# J7AEP_GPU_BXS464_WRAP0_GPU_SS_0_CORE_MMRS register map
Vendor: Texas Instruments
Registers are 64-bit, access per field, reset 0x0 unless marked. A register's access mark holds for its fields unless they carry their own. Offsets are as the file gives them; [hi:lo] are bit positions; lines under a group give offsets from that group; {n}, {i} and the like mark numbered series; 'fields as' and 'values as' point back to an identical list; <NAME> marks a mode.

## J7AEP_GPU_BXS464_WRAP0_GPU_SS_0_CORE_MMRS (part 4 of 4)
0x3970 CORE_MMRS_RGX_CR_SLC_SIZE_IN_KB ro reset 0x100
  [15:0] SIZE — The configured SLC SIZE in KBytes ie 0x0100 = 256 KB.
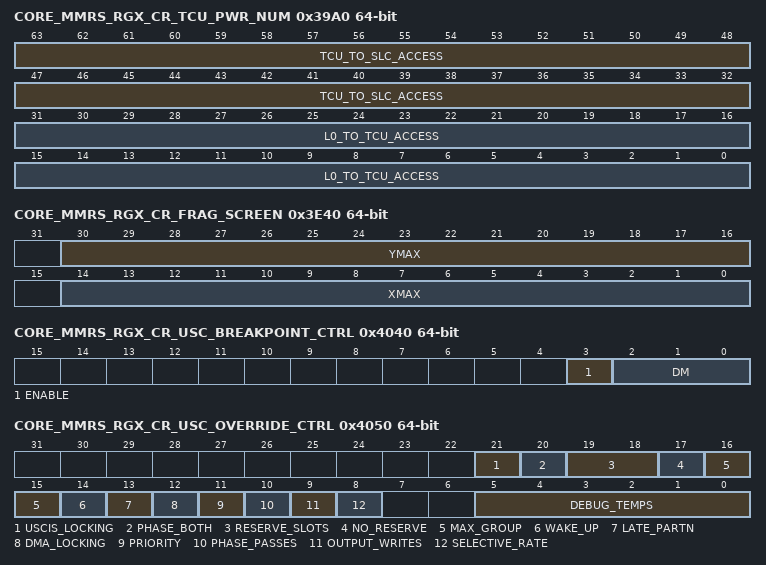
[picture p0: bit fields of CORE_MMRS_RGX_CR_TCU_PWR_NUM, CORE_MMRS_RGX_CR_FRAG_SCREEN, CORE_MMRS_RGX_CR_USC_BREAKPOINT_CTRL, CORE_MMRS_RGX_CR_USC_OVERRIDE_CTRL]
0x39A0 CORE_MMRS_RGX_CR_TCU_PWR_NUM ro
  [63:32] TCU_TO_SLC_ACCESS — Number of TCU to SLC accesses
  [31:0] L0_TO_TCU_ACCESS — Number of MADD-L0 to TCU accesses
0x39B0 CORE_MMRS_RGX_CR_TCU_CTRL
  [0] SLC_CP_LAZYWB_OVERRIDE rw — Override the TCU to SLC cache policy from lazy write back to write back
0x3E40 CORE_MMRS_RGX_CR_FRAG_SCREEN
  [30:16] YMAX rw — Maximum pixel number in y dimension on screen. Screen height in pixels is YMAX+1. 16K x 16K is the max screen size. I.e. 2^14, bit 15 is always written as 0.
  [14:0] XMAX rw — Maximum pixel number in x dimension on screen. Screen width in pixels is XMAX+1. 16K x 16K is the max screen size. I.e. 2^14, bit 15 is always written as 0.
0x4000 CORE_MMRS_RGX_CR_USC_INST_CACHE
  [0] INVALIDATE wo — Any write to this location invalidates the L1 and L2 instruction caches automatically
0x4008 CORE_MMRS_RGX_CR_USC_CODE_BASE_VERTEX
  [39:6] ADDR rw — Vertex Data Master Code Base Register bits
0x4010 CORE_MMRS_RGX_CR_USC_CODE_BASE_PIXEL
  [39:6] ADDR rw — Pixel Data Master Code Base Register bits
0x4028 CORE_MMRS_RGX_CR_USC_CODE_BASE_COMPUTE
  [39:6] ADDR rw — Compute Data Master Code Base Register bits
0x4030 CORE_MMRS_RGX_CR_USC_BREAKPOINT
  [31:1] ADDR rw — Breakpoint Address
0x4038 CORE_MMRS_RGX_CR_USC_BREAKPOINT_HANDLER
  [31:1] ADDR rw — Breakpoint Handler Address
0x4040 CORE_MMRS_RGX_CR_USC_BREAKPOINT_CTRL
  [3] ENABLE rw — 0 = Breakpoint disabled, 1 = Breakpoint enabled
  [2:0] DM rw — Data Master of Breakpoint
0x4048 CORE_MMRS_RGX_CR_USC_SMP_SWAP
  [0] ENABLE rw — Deactivate after SMP instruction
0x4050 CORE_MMRS_RGX_CR_USC_OVERRIDE_CTRL
  [21] USCIS_LOCKING rw — 0 = Default, enable locking of USCIS when queue fills to maintain task ordering, 1 = retry USCIS request
  [20] PHASE_BOTH rw — 0 = Default, no extra pass groups when single phase followed by multi-phase, 1 = generate pass group whenever phases per task changes
  [19:18] RESERVE_SLOTS rw — 0 = Default, allow all slots to be used for first phase tasks, 1 = reserve 1 slot, 2 = reserve 2, 3 = reserve 4
  [17] NO_RESERVE rw — 0 = Default, reserve slots for second phases, 1 = Do not reserve slots for second phase tasks
  [16:15] MAX_GROUP rw — 0 = Default - 8 pass groups in flight, 1 = 6 pass groups, 2 = 4 pass groups, 3 = 2 pass groups. To disable entirely see PDS
  [14] WAKE_UP rw — 0 = Default, normal wake up, 1 = force task wake up
  [13] LATE_PARTN rw — 0 = Default, enable pixel data master tasks to start before a partition is allocated, 1 = wait for partition
  [12] DMA_LOCKING rw — 0 = Default, enable locking of DMA when queue fills to maintain task ordering, 1 = retry DMA request
  [11] PRIORITY rw — 0 = Default, enable state loading and end of tile tasks to run with higher priority, 1 = all tasks low priority
  [10] PHASE_PASSES rw — 0 = Default, enable inferred pass groups when multiple phase tasks are encountered, 1 = disable, hard SDs must be used
  [9] OUTPUT_WRITES rw — 0 = Default, enable tracking of output buffer write completion for on-edge buffer validlity, 1 = tracking invalid
  [8] SELECTIVE_RATE rw — 0 = Default, [core specific, enable selective rate mode if functional], 1 = disable
  [5:0] DEBUG_TEMPS rw — Number of temps to add to PDS allocation size for debugging. Units of 8
0x4068 CORE_MMRS_RGX_CR_USC_SHARED_GROUP_CLEAR ro
  [0] PENDING — Any write to this location requests the USC Shared Group register file to be cleared
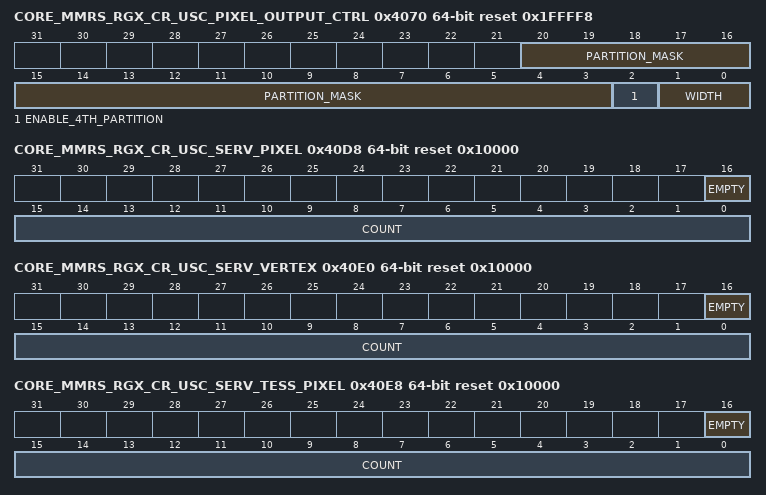
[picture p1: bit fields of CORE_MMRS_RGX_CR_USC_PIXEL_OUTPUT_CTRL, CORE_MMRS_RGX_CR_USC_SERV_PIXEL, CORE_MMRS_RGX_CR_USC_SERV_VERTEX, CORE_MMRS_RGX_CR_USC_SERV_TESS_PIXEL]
0x4070 CORE_MMRS_RGX_CR_USC_PIXEL_OUTPUT_CTRL reset 0x1FFFF8
  [20:3] PARTITION_MASK rw — Partition Enable Mask for USC pixel task
  [2] ENABLE_4TH_PARTITION rw — Enables 4th Partition
  [1:0] WIDTH rw
{0x4078+8i} CORE_MMRS_RGX_CR_USC_CLEAR_REGISTER{i} (i=0..3)
  [31:0] VAL rw — Clear Colour register {i}
{0x4098+8i} CORE_MMRS_RGX_CR_USC_G{i} (i=0..7)
  [7:0] P rw — Global, cross-thread-accessible read/write register for USC programs via the 'special' bank type
0x40D8 CORE_MMRS_RGX_CR_USC_SERV_PIXEL ro reset 0x10000
  [16] EMPTY — No Pixel Data Master tasks in USC0 queue
  [15:0] COUNT — Number of Pixel Data Master tasks serviced by USC0
0x40E0 CORE_MMRS_RGX_CR_USC_SERV_VERTEX ro reset 0x10000
  [16] EMPTY — No Vertex Data Master tasks in USC0 queue
  [15:0] COUNT — Number of Vertex Data Master tasks serviced by USC0
0x40E8 CORE_MMRS_RGX_CR_USC_SERV_TESS_PIXEL ro reset 0x10000
  [16] EMPTY — No Tessellator Pixel Data Master tasks in USC0 queue
  [15:0] COUNT — Number of Tessellator Pixel Data Master tasks serviced by USC0
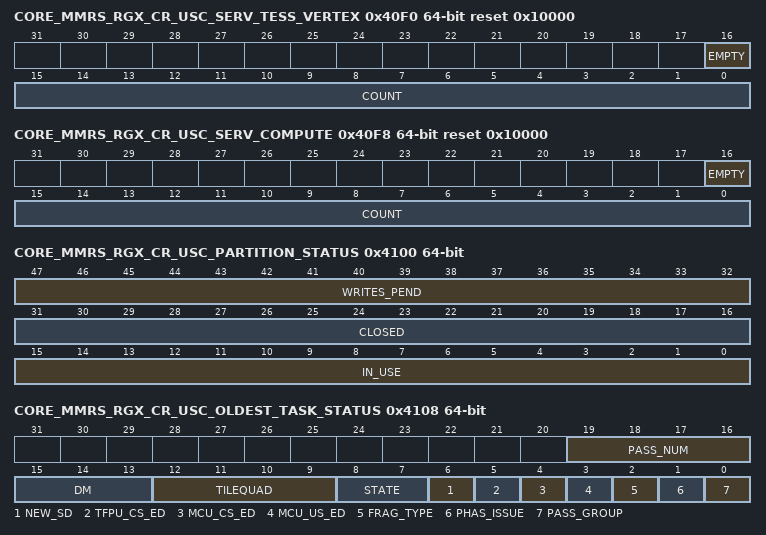
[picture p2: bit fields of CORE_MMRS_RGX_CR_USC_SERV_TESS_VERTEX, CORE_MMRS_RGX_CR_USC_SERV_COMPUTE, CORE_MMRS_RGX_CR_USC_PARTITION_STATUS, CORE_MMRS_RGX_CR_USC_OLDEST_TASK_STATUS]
0x40F0 CORE_MMRS_RGX_CR_USC_SERV_TESS_VERTEX ro reset 0x10000
  [16] EMPTY — No Tessellator Vertex Data Master tasks in USC0 queue
  [15:0] COUNT — Number of Tessellator Vertex Data Master tasks serviced by USC0
0x40F8 CORE_MMRS_RGX_CR_USC_SERV_COMPUTE ro reset 0x10000
  [16] EMPTY — No Compute Data Master tasks in USC0 queue
  [15:0] COUNT — Number of Compute Data Master tasks serviced by USC0
0x4100 CORE_MMRS_RGX_CR_USC_PARTITION_STATUS ro
  [47:32] WRITES_PEND — Partition writes pending
  [31:16] CLOSED — Partition closed - end of tile task started
  [15:0] IN_USE — Partition in use
0x4108 CORE_MMRS_RGX_CR_USC_OLDEST_TASK_STATUS ro
  [19:16] PASS_NUM — The present pass group
  [15:13] DM — The task Data Master
  [12:9] TILEQUAD — The stream of the task, depends on Data Master Vertex: Indicates the patch of the task Pixel, >= 4 cluster: The tile ID of the task Pixel, 2 cluster: The tile ID and patch concatenated Compute: 0
  [8:7] STATE — Queue state for entry
  [6] NEW_SD — This task is at the start of a new SD group, bit is cleared when the task is first run
  [5] TFPU_CS_ED — This task is waiting for a TFPU strobe, which has not been satisfied
  [4] MCU_CS_ED — This task is waiting for an MCU CS strobe, which has not been satisfied
  [3] MCU_US_ED — This task is waiting for an MCU US strobe, which has not been satisfied
  [2] FRAG_TYPE — Is this task a work or state loading type. '1' indicates a Vertex/Fragment/Work type, '0' indicates a Shared/ Coefficient/ Control type
  [1] PHAS_ISSUE — This task must issue a PHAS instruction, which has not yet been seen
  [0] PASS_GROUP — Is the task the start of a new pass group
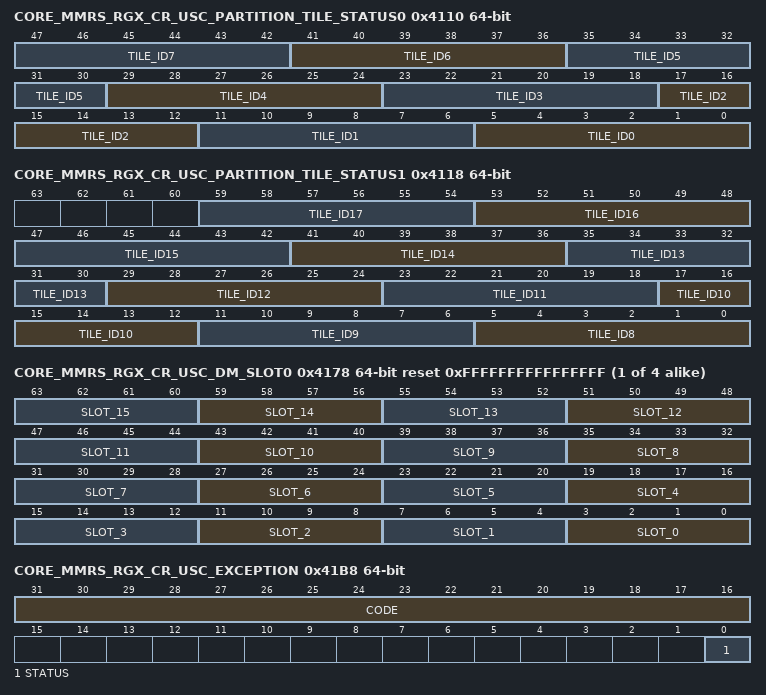
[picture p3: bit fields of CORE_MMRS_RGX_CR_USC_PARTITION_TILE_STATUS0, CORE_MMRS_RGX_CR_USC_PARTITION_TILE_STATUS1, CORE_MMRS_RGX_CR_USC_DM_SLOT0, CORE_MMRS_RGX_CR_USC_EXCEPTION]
0x4110 CORE_MMRS_RGX_CR_USC_PARTITION_TILE_STATUS0 ro
  [6n+5:6n] TILE_ID{n} (n=0..7) — Tile ID for partition {n}
0x4118 CORE_MMRS_RGX_CR_USC_PARTITION_TILE_STATUS1 ro
  [6n-43:6n-48] TILE_ID{n} (n=8..17) — Tile ID for partition {n}
{0x4178+8i} CORE_MMRS_RGX_CR_USC_DM_SLOT{i} ro reset 0xFFFFFFFFFFFFFFFF (i=0..3)
  [4n+3:4n] SLOT_{n} (n=0..15)
0x41B8 CORE_MMRS_RGX_CR_USC_EXCEPTION ro
  [31:16] CODE — Cluster exception code
  [0] STATUS — 1=Cluster has raised an exception
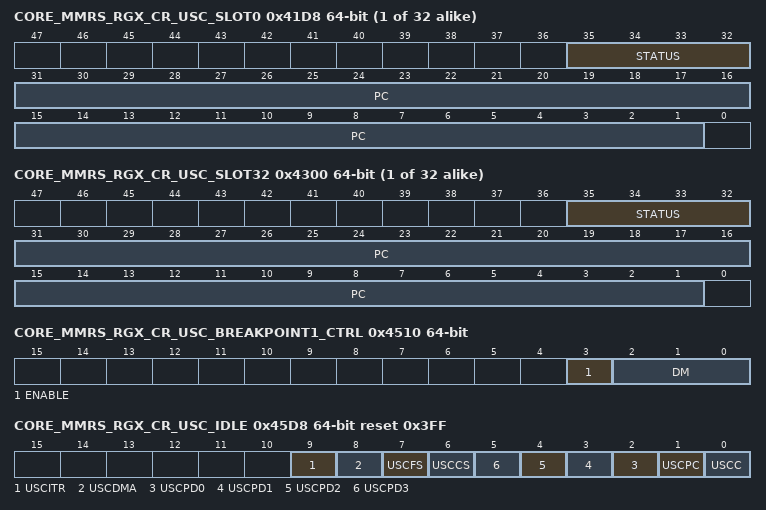
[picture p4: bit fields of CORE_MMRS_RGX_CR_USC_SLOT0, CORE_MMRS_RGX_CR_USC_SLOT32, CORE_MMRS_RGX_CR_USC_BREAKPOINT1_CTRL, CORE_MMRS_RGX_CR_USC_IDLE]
{0x41D8+8i} CORE_MMRS_RGX_CR_USC_SLOT{i} ro (i=0..31)
  [35:32] STATUS, [31:1] PC
{0x4200+8i} CORE_MMRS_RGX_CR_USC_SLOT{i} ro (i=32..63)
  [35:32] STATUS, [31:1] PC
0x4500 CORE_MMRS_RGX_CR_USC_BREAKPOINT1
  [31:1] ADDR rw — Breakpoint Address
0x4508 CORE_MMRS_RGX_CR_USC_BREAKPOINT1_HANDLER
  [31:1] ADDR rw — Breakpoint Handler Address
0x4510 CORE_MMRS_RGX_CR_USC_BREAKPOINT1_CTRL
  fields as CORE_MMRS_RGX_CR_USC_BREAKPOINT_CTRL
0x45D8 CORE_MMRS_RGX_CR_USC_IDLE ro reset 0x3FF
  [9] USCITR — USCITR idle
  [8] USCDMA — USCDMA idle
  [7] USCFS — USCFS idle
  [6] USCCS — USCCS idle
  [n+2] USCPD{n} (n=0..3) — USCPD idle
  [1] USCPC — USCPC idle
  [0] USCC — USCC idle
0x45E8 CORE_MMRS_RGX_CR_USC_ITRCOEFF_CACHE
  [0] BYPASS rw — Bypass bit of the coefficient cache
0x45F0 CORE_MMRS_RGX_CR_USC_ITRSMP_STATE_CACHE
  [0] BYPASS rw — Bypass bit of the state cache
0x4600 CORE_MMRS_RGX_CR_USC_PWR_INSTR ro
  [31:0] EXEC — Number of instructions executed [max 1 per clock]
0x4608 CORE_MMRS_RGX_CR_USC_PWR_CMMN_STR_ACCESS ro
  [31:0] COUNT — Number of Common Store accesses [max of 4 per lock]
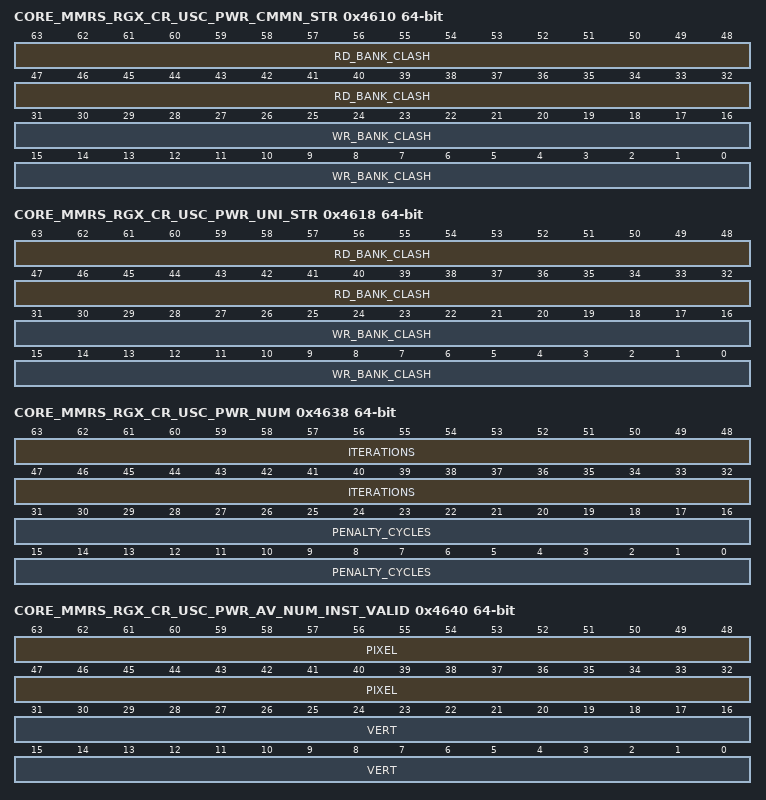
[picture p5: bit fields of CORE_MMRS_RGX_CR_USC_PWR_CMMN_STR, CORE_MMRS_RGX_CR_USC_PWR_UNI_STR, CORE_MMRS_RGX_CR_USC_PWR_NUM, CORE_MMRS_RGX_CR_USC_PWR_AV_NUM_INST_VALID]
0x4610 CORE_MMRS_RGX_CR_USC_PWR_CMMN_STR ro
  [63:32] RD_BANK_CLASH — Common Store: Number of read/read bank clashes
  [31:0] WR_BANK_CLASH — Common Store: Number of write/write bank clashes
0x4618 CORE_MMRS_RGX_CR_USC_PWR_UNI_STR ro
  [63:32] RD_BANK_CLASH — Unified Store: Number of read/read bank clashes
  [31:0] WR_BANK_CLASH — Unified Store: Number of write/write bank clashes
0x4620 CORE_MMRS_RGX_CR_USC_PWR_NUM_FLOAT ro
  [31:0] OPS — Number of floating point ops; FAdd/Fmul=1, MAD=2; max 32x2=64 per clock
0x4628 CORE_MMRS_RGX_CR_USC_PWR_NUM_INTEGER ro
  [31:0] OPS — Number of integer ops; Add/Mul=1, MAD=2, max 16*2=32 per clock
0x4630 CORE_MMRS_RGX_CR_USC_PWR_NUM_COALU ro
  [31:0] OPS — Number of COALU ops; max of 16 per clock
0x4638 CORE_MMRS_RGX_CR_USC_PWR_NUM ro
  [63:32] ITERATIONS — Number of iterates
  [31:0] PENALTY_CYCLES — Penalty cycles for read/read and write/write clashes. For each instruction this is max[a,b,c,d]
0x4640 CORE_MMRS_RGX_CR_USC_PWR_AV_NUM_INST_VALID ro
  [63:32] PIXEL — Average number of instances valid out of 16 for pixel tasks
  [31:0] VERT — Average number of instances valid out of 16 for vertex tasks
0x4648 CORE_MMRS_RGX_CR_USC_PWR_NUM_ON_EDGE_PIXL ro
  [31:0] WRITE — Number of on-edge pixel output register writes
0x4650 CORE_MMRS_RGX_CR_USC_PWR_NUM_OFF_EDGE_PIXL ro
  [31:0] WRITE — Number of off-edge pixel output register writes
0x4658 CORE_MMRS_RGX_CR_USC_PWR_NUM_F16 ro
  [31:0] OPS — Number of F16 operations. Max of 16
0x4660 CORE_MMRS_RGX_CR_USC_PWR_USCPD_INSTR ro
  [31:0] COUNT — Number of instructions executed by USCPD
0x4668 CORE_MMRS_RGX_CR_USC_PWR_INT_REG_ACCESS ro
  [31:0] COUNT — Number of internal register accesses. Max 128 per clock = 8 registers * 16 instances
0x4670 CORE_MMRS_RGX_CR_USC_PWR_US_STR_ACCESS ro
  [31:0] COUNT — Number of unified sotre US bank accesses. Max of 32 per clock = 8 banks * 4 pipes
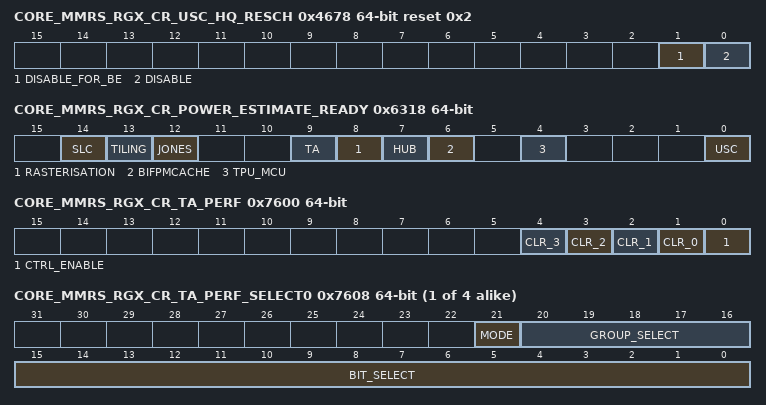
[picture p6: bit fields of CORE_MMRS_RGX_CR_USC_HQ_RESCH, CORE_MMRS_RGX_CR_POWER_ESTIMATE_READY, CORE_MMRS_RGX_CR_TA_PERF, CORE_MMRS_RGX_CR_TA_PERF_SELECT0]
0x4678 CORE_MMRS_RGX_CR_USC_HQ_RESCH reset 0x2
  [1] DISABLE_FOR_BE rw — Disable rescheduling for BE instr in USCPC
  [0] DISABLE rw — Disable rescheduling in USCPC
{0x5000+8i} CORE_MMRS_RGX_CR_USC_UVS{i}_CHECKSUM ro (i=0..3)
  [31:0] VALUE — Checksum of USC to UVS writes from USC{i}
0x5020 CORE_MMRS_RGX_CR_PPP_SIGNATURE ro
  [31:0] VALUE — Signature of PPP to Clipper Interface
0x5028 CORE_MMRS_RGX_CR_TE_SIGNATURE ro
  [31:0] VALUE — Signature of TE control stream writes
0x5030 CORE_MMRS_RGX_CR_VCE_CHECKSUM ro
  [31:0] VALUE — Checksum of VCE memory writes
0x5038 CORE_MMRS_RGX_CR_ISP_PDS_CHECKSUM ro
  [31:0] VALUE — Checksum of ISP PDS Span Output
0x5040 CORE_MMRS_RGX_CR_ISP_TPF_CHECKSUM ro
  [31:0] VALUE — Checksum of ISP TPF Object Output
0x5048 CORE_MMRS_RGX_CR_TFPU_PLANE0_CHECKSUM ro
  [31:0] VALUE — Checksum of TFPU Plane0 Output
0x5050 CORE_MMRS_RGX_CR_TFPU_PLANE1_CHECKSUM ro
  [31:0] VALUE — Checksum of TFPU Plane1 Output
0x5058 CORE_MMRS_RGX_CR_PBE_CHECKSUM ro
  [31:0] VALUE — Checksum of PBE memory writes
0x5060 CORE_MMRS_RGX_CR_PDS_DOUTM_STM_SIGNATURE ro
  [31:0] VALUE — Signature of PDS DOUTM Stream Out MCU writes
0x5068 CORE_MMRS_RGX_CR_IFPU_ISP_CHECKSUM ro
  [31:0] VALUE — Checksum of IFPU Output
0x5070 CORE_MMRS_RGX_CR_MCU_L0_TA_CHECKSUM ro
  [31:0] VALUE — Checksum of the PDS->USC from MCU for TA data
0x5078 CORE_MMRS_RGX_CR_MCU_L0_3D_CHECKSUM ro
  [31:0] VALUE — Checksum of the PDS->USC from MCU for 3D data
0x5080 CORE_MMRS_RGX_CR_MCU_L0_WRAP_TA_CHECKSUM ro
  [31:0] VALUE — Checksum of the PDS->USC from MCU for TA data
0x5088 CORE_MMRS_RGX_CR_MCU_L0_WRAP_3D_CHECKSUM ro
  [31:0] VALUE — Checksum of the PDS->USC from MCU for 3D data
0x5100 CORE_MMRS_RGX_CR_USC_UVS4_CHECKSUM ro
  [31:0] VALUE — Checksum of USC to UVS writes from USC4
0x5108 CORE_MMRS_RGX_CR_USC_UVS5_CHECKSUM ro
  [31:0] VALUE — Checksum of USC to UVS writes from USC5
0x5160 CORE_MMRS_RGX_CR_PBE_CHECKSUM_NO_ADDR ro
  [31:0] VALUE — No address checksum of PBE memory writes
0x6000 CORE_MMRS_RGX_CR_PERF_COUNTER
  [0] RESET rw — A write of 1 to this register resets the Cycle Counters and holds them in Reset. A write of 0 enables them for Counting
0x6008 CORE_MMRS_RGX_CR_PERF_TA_PHASE ro
  [31:0] COUNT — The number of TA phases completed
0x6010 CORE_MMRS_RGX_CR_PERF_3D_PHASE ro
  [31:0] COUNT — The number of 3D phases completed
0x6018 CORE_MMRS_RGX_CR_PERF_COMPUTE_PHASE ro
  [31:0] COUNT — The number of Compute phases completed
0x6020 CORE_MMRS_RGX_CR_PERF_TA_CYCLE ro
  [31:0] COUNT — The number of cycles spent in TA phases
0x6028 CORE_MMRS_RGX_CR_PERF_3D_CYCLE ro
  [31:0] COUNT — The number of cycles spent in 3D phases
0x6030 CORE_MMRS_RGX_CR_PERF_COMPUTE_CYCLE ro
  [31:0] COUNT — The number of cycles spent in Compute phases
0x6038 CORE_MMRS_RGX_CR_PERF_TA_OR_3D_CYCLE ro
  [31:0] COUNT — The number of cycles spent in TA phases or 3D phases
0x6040 CORE_MMRS_RGX_CR_PERF_INITIAL_TA_CYCLE ro
  [31:0] COUNT — The number of cycles spent in TA phases before the first 3D phase
0x6048 CORE_MMRS_RGX_CR_PERF_FINAL_3D_CYCLE ro
  [31:0] COUNT — The number of cycles spent in the last 3D phase
0x6050 CORE_MMRS_RGX_CR_PERF_BIF0_READ ro
  [31:0] COUNT — The number of BIF0-to-SLC reads
0x6058 CORE_MMRS_RGX_CR_PERF_BIF0_WRITE ro
  [31:0] COUNT — The number of BIF0-to-SLC writes
0x6060 CORE_MMRS_RGX_CR_PERF_BIF0_BYTE_WRITE ro
  [31:0] COUNT — The number of BIF0-to-SLC bytes written
0x6068 CORE_MMRS_RGX_CR_PERF_BIF0_READ_STALL ro
  [31:0] COUNT — The number of BIF0-to-SLC read stalls
0x6070 CORE_MMRS_RGX_CR_PERF_BIF0_WRITE_STALL ro
  [31:0] COUNT — The number of BIF0-to-SLC write stalls
0x60A0 CORE_MMRS_RGX_CR_PERF_SLC0_READ ro
  [31:0] COUNT — The number of SLC-to-MEM interface 0 reads
0x60A8 CORE_MMRS_RGX_CR_PERF_SLC0_WRITE ro
  [31:0] COUNT — The number of SLC-to-MEM interface 0 writes
0x60B0 CORE_MMRS_RGX_CR_PERF_SLC0_BYTE_WRITE ro
  [31:0] COUNT — The number of SLC-to-MEM interface 0 bytes written
0x60B8 CORE_MMRS_RGX_CR_PERF_SLC0_READ_STALL ro
  [31:0] COUNT — The number of SLC-to-MEM interface 0 command stalls
0x60C0 CORE_MMRS_RGX_CR_PERF_SLC0_WRITE_STALL ro
  [31:0] COUNT — The number of SLC-to-MEM insterface 0 write channel stalls
0x60F0 CORE_MMRS_RGX_CR_PERF_SLC_BURST_SIZE0_IN ro
  [31:0] VALUE — The number of burstlength 0 accesses into the Burst Combiner
0x60F8 CORE_MMRS_RGX_CR_PERF_SLC_BURST_SIZE1_IN ro
  [31:0] VALUE — The number of burstlength 1 accesses into the Burst Combiner
{0x6100+8i} CORE_MMRS_RGX_CR_PERF_SLC_BURST_SIZE{i}_OUT ro (i=0..2)
  [31:0] VALUE — The number of burstlength {i} accesses out of the Burst Combiner
0x6118 CORE_MMRS_RGX_CR_PERF_SLC0_READ_ID_STALL ro
  [31:0] COUNT — The number of cycles the SLC spends stalled because all Read IDs on memory interface 0 are currently in use
0x6120 CORE_MMRS_RGX_CR_PERF_SLC0_WRITE_ID_STALL ro
  [31:0] COUNT — The number of cycles the SLC spends stalled because all Write IDs on memory interface 0 are currently in use
0x6138 CORE_MMRS_RGX_CR_PERF_SLC_BURST_SIZE3_OUT ro
  [31:0] VALUE — The number of burstlength 3 accesses out of the Burst Combiner
0x6190 CORE_MMRS_RGX_CR_PERF_SLC_BURST_SIZE2_IN ro
  [31:0] VALUE — The number of burstlength 2 accesses into the Burst Combiner
0x6198 CORE_MMRS_RGX_CR_PERF_SLC_BURST_SIZE3_IN ro
  [31:0] VALUE — The number of burstlength 3 accesses into the Burst Combiner
0x6220 CORE_MMRS_RGX_CR_PERF_3D_SPINUP ro
  [31:0] CYCLES — The number of cycles it takes the 3D pipeline to spin-up
0x6300 CORE_MMRS_RGX_CR_POWER_ESTIMATE_REQ_RST
  [0] VALUE rw
0x6310 CORE_MMRS_RGX_CR_POWER_ESTIMATE_SAMPLE_COUNT
  [31:0] VALUE rw
0x6318 CORE_MMRS_RGX_CR_POWER_ESTIMATE_READY ro
  [14] SLC, [13] TILING, [12] JONES, [9] TA, [8] RASTERISATION, [7] HUB, [6] BIFPMCACHE, [4] TPU_MCU, [0] USC
0x6320 CORE_MMRS_RGX_CR_POWER_ESTIMATE_GAIN_COEFF
  [31:0] VALUE rw
0x6328 CORE_MMRS_RGX_CR_POWER_ESTIMATE_RESULT
  [31:0] VALUE rw
0x6330 CORE_MMRS_RGX_CR_PERF_COUNT_MODE_ONLY
  [0] VALUE rw
0x6500 CORE_MMRS_RGX_CR_AVG_NON_CRITICAL_MEM0_LATENCY ro
  [11:0] COUNT — The average number of read latency cycles incur at external memory for non critical tag
0x6508 CORE_MMRS_RGX_CR_MIN_NON_CRITICAL_MEM0_LATENCY ro reset 0xFFF
  [11:0] COUNT — The min number of read latency cycles incur at external memory for non critical tag
0x6510 CORE_MMRS_RGX_CR_MAX_NON_CRITICAL_MEM0_LATENCY ro
  [11:0] COUNT — The max number of read latency cycles incur at external memory for non critical tag
0x6518 CORE_MMRS_RGX_CR_AVG_CRITICAL_MEM0_LATENCY ro
  [11:0] COUNT — The average number of read latency cycles incur at external memory for critical tag
0x6520 CORE_MMRS_RGX_CR_MIN_CRITICAL_MEM0_LATENCY ro reset 0xFFF
  [11:0] COUNT — The min number of read latency cycles incur at external memory for critical tag
0x6528 CORE_MMRS_RGX_CR_MAX_CRITICAL_MEM0_LATENCY ro
  [11:0] COUNT — The max number of read latency cycles incur at external memory for critical tag
0x6530 CORE_MMRS_RGX_CR_USER_DEFINED_MEM0_MH_TAG
  [6:0] VALUE rw
0x6538 CORE_MMRS_RGX_CR_AVG_USER_MH_TAG_MEM0_LATENCY ro
  [11:0] COUNT — The average number of read latency cycles incur at external memory for user_defined tag
0x6540 CORE_MMRS_RGX_CR_MIN_USER_MH_TAG_MEM0_LATENCY ro reset 0xFFF
  [11:0] COUNT — The min number of read latency cycles incur at external memory for user defined tag
0x6548 CORE_MMRS_RGX_CR_MAX_USER_MH_TAG_MEM0_LATENCY ro
  [11:0] COUNT — The max number of read latency cycles incur at external memory for user defined tag
0x6550 CORE_MMRS_RGX_CR_MIN_NON_CRITICAL_MEM0_LATENCY_MH_TAG ro
  [5:0] VALUE — The mh_tag value of min read latency cycles for non critical tag
0x6558 CORE_MMRS_RGX_CR_MAX_NON_CRITICAL_MEM0_LATENCY_MH_TAG ro
  [5:0] VALUE — The mh_tag value of max read latency cycles for non critical tag
0x7600 CORE_MMRS_RGX_CR_TA_PERF
  [n+1] CLR_{n} rw (n=0..3) — clear counter {n}
  [0] CTRL_ENABLE rw — enables the perf bus counters
{0x7608+8i} CORE_MMRS_RGX_CR_TA_PERF_SELECT{i} (i=0..3)
  [21] MODE rw — reduction mode, 0: bitwise increments, 1: unsigned count increment
  [20:16] GROUP_SELECT rw — group select, see full PERF documentation for signals in each group
  [15:0] BIT_SELECT rw — bit mask for enabled signals in group
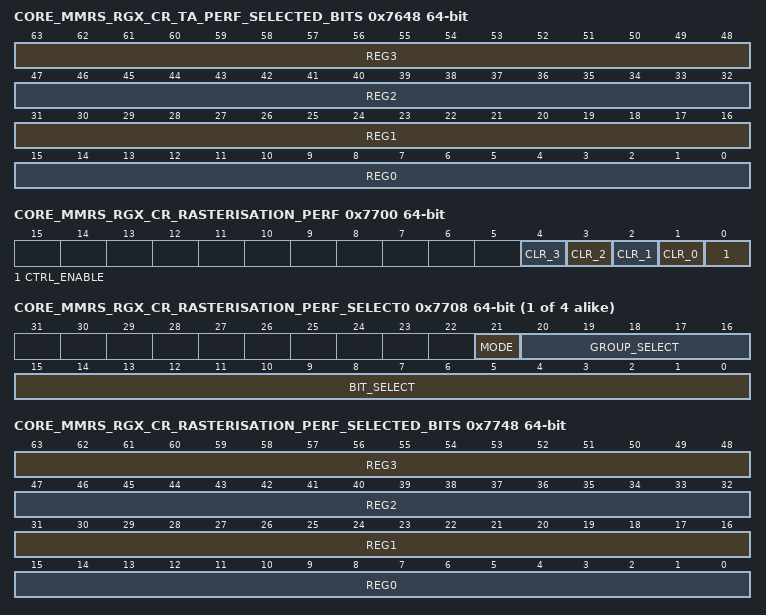
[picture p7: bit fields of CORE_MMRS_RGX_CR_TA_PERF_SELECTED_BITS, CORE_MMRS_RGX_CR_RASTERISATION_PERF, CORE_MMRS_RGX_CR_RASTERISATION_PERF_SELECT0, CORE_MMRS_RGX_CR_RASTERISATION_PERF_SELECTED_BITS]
0x7648 CORE_MMRS_RGX_CR_TA_PERF_SELECTED_BITS ro
  [63:48] REG3 — present bus signals counter 3
  [47:32] REG2 — present bus signals counter 2
  [31:16] REG1 — persent bus signals counter 1
  [15:0] REG0 — present bus signals counter 0
{0x7650+8i} CORE_MMRS_RGX_CR_TA_PERF_COUNTER_{i} ro (i=0..3)
  [31:0] REG — counter a0
0x7700 CORE_MMRS_RGX_CR_RASTERISATION_PERF
  fields as CORE_MMRS_RGX_CR_TA_PERF
{0x7708+8i} CORE_MMRS_RGX_CR_RASTERISATION_PERF_SELECT{i} (i=0..3)
  [21] MODE rw — reduction mode, 0: bitwise increments, 1: unsigned count increment
  [20:16] GROUP_SELECT rw — group select, see full PERF documenrasterisationtion for signals in each group
  [15:0] BIT_SELECT rw — bit mask for enabled signals in group
0x7748 CORE_MMRS_RGX_CR_RASTERISATION_PERF_SELECTED_BITS ro
  fields as CORE_MMRS_RGX_CR_TA_PERF_SELECTED_BITS
{0x7750+8i} CORE_MMRS_RGX_CR_RASTERISATION_PERF_COUNTER_{i} ro (i=0..3)
  [31:0] REG — counter a0
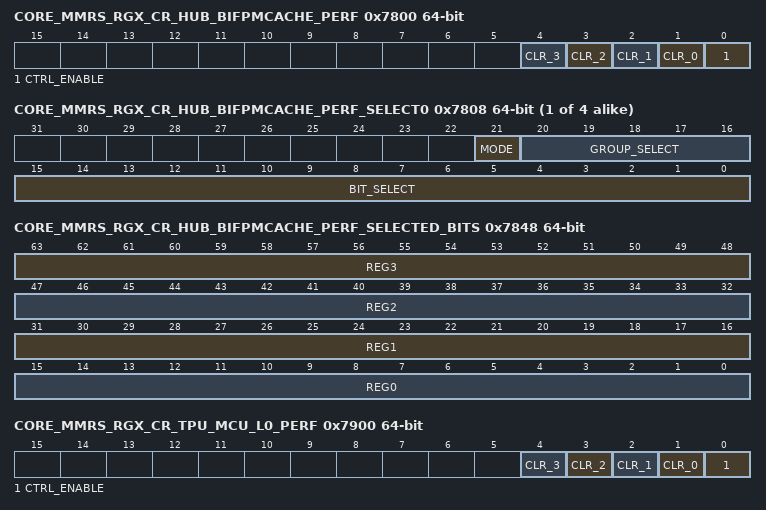
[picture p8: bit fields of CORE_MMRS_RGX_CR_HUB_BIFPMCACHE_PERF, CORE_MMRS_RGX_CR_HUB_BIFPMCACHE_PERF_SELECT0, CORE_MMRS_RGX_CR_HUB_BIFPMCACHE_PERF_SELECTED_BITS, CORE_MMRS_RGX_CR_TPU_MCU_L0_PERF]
0x7800 CORE_MMRS_RGX_CR_HUB_BIFPMCACHE_PERF
  fields as CORE_MMRS_RGX_CR_TA_PERF
{0x7808+8i} CORE_MMRS_RGX_CR_HUB_BIFPMCACHE_PERF_SELECT{i} (i=0..3)
  [21] MODE rw — reduction mode, 0: bitwise increments, 1: unsigned count increment
  [20:16] GROUP_SELECT rw — group select, see full PERF documenhub_bifpmcachetion for signals in each group
  [15:0] BIT_SELECT rw — bit mask for enabled signals in group
0x7848 CORE_MMRS_RGX_CR_HUB_BIFPMCACHE_PERF_SELECTED_BITS ro
  fields as CORE_MMRS_RGX_CR_TA_PERF_SELECTED_BITS
{0x7850+8i} CORE_MMRS_RGX_CR_HUB_BIFPMCACHE_PERF_COUNTER_{i} ro (i=0..3)
  [31:0] REG — counter a0
0x7900 CORE_MMRS_RGX_CR_TPU_MCU_L0_PERF
  fields as CORE_MMRS_RGX_CR_TA_PERF
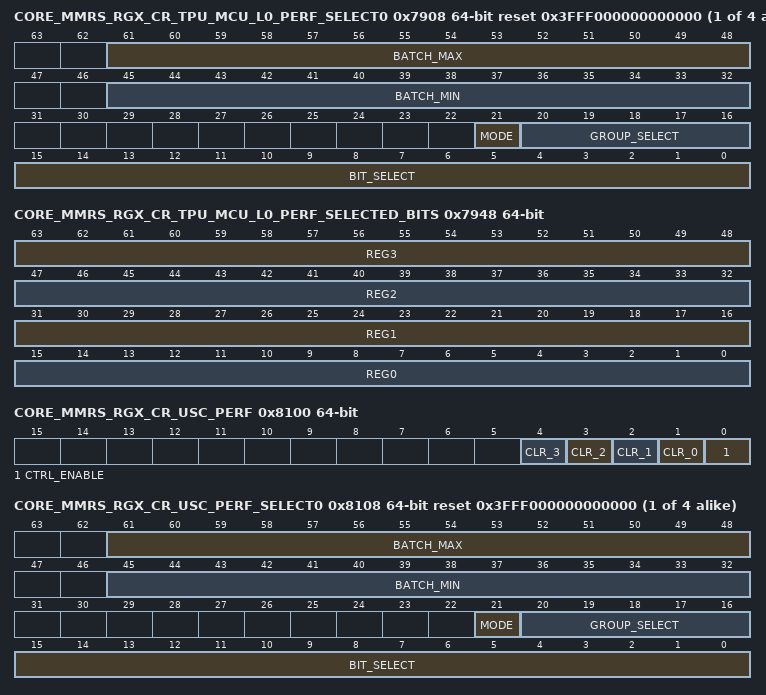
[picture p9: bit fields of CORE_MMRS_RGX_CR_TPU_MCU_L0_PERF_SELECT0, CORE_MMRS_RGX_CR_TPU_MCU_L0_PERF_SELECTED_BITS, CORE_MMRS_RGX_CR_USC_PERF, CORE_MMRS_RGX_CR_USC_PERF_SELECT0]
{0x7908+8i} CORE_MMRS_RGX_CR_TPU_MCU_L0_PERF_SELECT{i} reset 0x3FFF000000000000 (i=0..3)
  [61:48] BATCH_MAX rw — this is the min batch number which will be counted in this group
  [45:32] BATCH_MIN rw — this is the min batch number which will be counted in this group
  [21] MODE rw — reduction mode, 0: bitwise increments, 1: unsigned count increment
  [20:16] GROUP_SELECT rw — group select, see full PERF documentation for signals in each group
  [15:0] BIT_SELECT rw — bit mask for enabled signals in group
0x7948 CORE_MMRS_RGX_CR_TPU_MCU_L0_PERF_SELECTED_BITS ro
  fields as CORE_MMRS_RGX_CR_TA_PERF_SELECTED_BITS
{0x7950+8i} CORE_MMRS_RGX_CR_TPU_MCU_L0_PERF_COUNTER_{i} ro (i=0..3)
  [31:0] REG — counter a0
0x8020 CORE_MMRS_RGX_CR_USC_TPU_LOW_PRECISION_ENABLE
  [0] VALUE rw
0x8100 CORE_MMRS_RGX_CR_USC_PERF
  fields as CORE_MMRS_RGX_CR_TA_PERF
{0x8108+8i} CORE_MMRS_RGX_CR_USC_PERF_SELECT{i} reset 0x3FFF000000000000 (i=0..3)
  [61:48] BATCH_MAX rw — this is the min batch number which will be counted in this group
  [45:32] BATCH_MIN rw — this is the min batch number which will be counted in this group
  [21] MODE rw — reduction mode, 0: bitwise increments, 1: unsigned count increment
  [20:16] GROUP_SELECT rw — group select, see full PERF documenusction for signals in each group
  [15:0] BIT_SELECT rw — bit mask for enabled signals in group
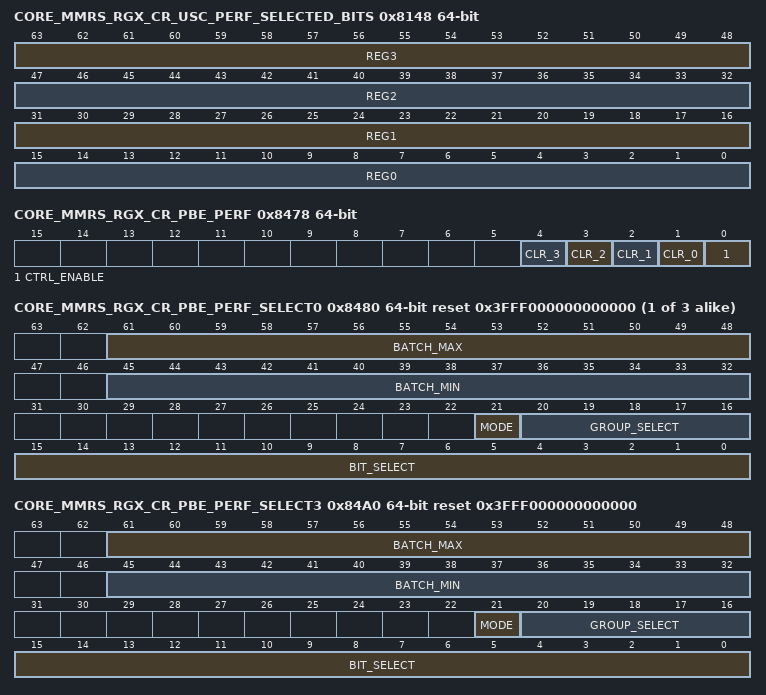
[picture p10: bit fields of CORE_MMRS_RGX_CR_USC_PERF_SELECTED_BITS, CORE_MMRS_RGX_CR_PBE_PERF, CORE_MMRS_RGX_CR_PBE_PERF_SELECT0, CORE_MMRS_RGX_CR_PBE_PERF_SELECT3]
0x8148 CORE_MMRS_RGX_CR_USC_PERF_SELECTED_BITS ro
  fields as CORE_MMRS_RGX_CR_TA_PERF_SELECTED_BITS
{0x8150+8i} CORE_MMRS_RGX_CR_USC_PERF_COUNTER_{i} ro (i=0..3)
  [31:0] REG — counter a0
0x8478 CORE_MMRS_RGX_CR_PBE_PERF
  fields as CORE_MMRS_RGX_CR_TA_PERF
{0x8480+8i} CORE_MMRS_RGX_CR_PBE_PERF_SELECT{i} reset 0x3FFF000000000000 (i=0..2)
  [61:48] BATCH_MAX rw — this is the max batch number which will be counted in this group
  [45:32] BATCH_MIN rw — this is the min batch number which will be counted in this group
  [21] MODE rw — reduction mode, 0: bitwise increments, 1: unsigned count increment
  [20:16] GROUP_SELECT rw — group select, see full PERF documentation for signals in each group
  [15:0] BIT_SELECT rw — bit mask for enabled signals in group
0x84A0 CORE_MMRS_RGX_CR_PBE_PERF_SELECT3 reset 0x3FFF000000000000
  fields as CORE_MMRS_RGX_CR_PBE_PERF_SELECT0
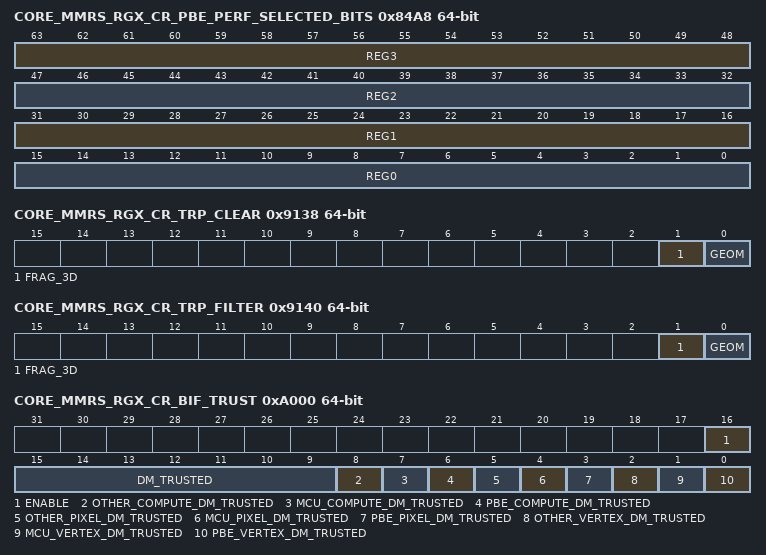
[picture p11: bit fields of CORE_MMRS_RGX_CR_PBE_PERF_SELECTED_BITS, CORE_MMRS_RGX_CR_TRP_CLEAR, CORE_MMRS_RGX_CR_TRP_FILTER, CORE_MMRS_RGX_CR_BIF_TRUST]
0x84A8 CORE_MMRS_RGX_CR_PBE_PERF_SELECTED_BITS ro
  fields as CORE_MMRS_RGX_CR_TA_PERF_SELECTED_BITS
{0x84B0+8i} CORE_MMRS_RGX_CR_PBE_PERF_COUNTER_{i} ro (i=0..3)
  [31:0] REG — counter a0
0x9100 CORE_MMRS_RGX_CR_TRP_CHECKSUM_PBE_3D ro
  [31:0] VALUE
0x9110 CORE_MMRS_RGX_CR_TRP_CHECKSUM_ZLS_UNCOMPRESSED ro
  [31:0] VALUE
0x9118 CORE_MMRS_RGX_CR_TRP_CHECKSUM_ZLS_COMPRESSED ro
  [31:0] VALUE
0x9120 CORE_MMRS_RGX_CR_TRP_CHECKSUM_TPW ro
  [31:0] VALUE
0x9128 CORE_MMRS_RGX_CR_TRP_CHECKSUM_TE_REGION ro
  [31:0] VALUE
0x9130 CORE_MMRS_RGX_CR_TRP_CHECKSUM_TE_CONTROL ro
  [31:0] VALUE
0x9138 CORE_MMRS_RGX_CR_TRP_CLEAR
  [1] FRAG_3D wo, [0] GEOM wo
0x9140 CORE_MMRS_RGX_CR_TRP_FILTER
  [1] FRAG_3D rw, [0] GEOM rw
0x9148 CORE_MMRS_RGX_CR_USC_DMA_CHECKSUM_DATA_COMP ro
  [31:0] VALUE
0x9150 CORE_MMRS_RGX_CR_USC_DMA_CHECKSUM_OP_COMP
  [0] CLEAR wo
0x9158 CORE_MMRS_RGX_CR_USC_DMA_HEAP_COMP
  [39:12] STRIDE rw
0x9160 CORE_MMRS_RGX_CR_TRP_DUMMY_PM
  [0] CLEAR wo — Clear Dummy PM allocations, a write to this register results in a one cycle pulse
0x9168 CORE_MMRS_RGX_CR_TRP_DUMMY_PM_TE_PAGE
  [33:13] ADDR rw
0x9170 CORE_MMRS_RGX_CR_TRP_DUMMY_PM_TPW_PAGE
  [33:13] ADDR rw
0xA000 CORE_MMRS_RGX_CR_BIF_TRUST
  [16] ENABLE rw — Enable Security feature: 0x1 = Enabled, 0x0 = Disabled
  [15:9] DM_TRUSTED rw — Mask of bits which defines which of the remaining Data Masters are trusted: 0x1 = Trusted, 0x0 = Untrusted
  [8] OTHER_COMPUTE_DM_TRUSTED rw — Defines whether other accesses with the Compute DM are trusted: 0x1 = Trusted, 0x0 = Untrusted
  [7] MCU_COMPUTE_DM_TRUSTED rw — Defines whether MCU accesses with the Compute DM are trusted: 0x1 = Trusted, 0x0 = Untrusted
  [6] PBE_COMPUTE_DM_TRUSTED rw — Defines whether PBE accesses with the Compute DM are trusted: 0x1 = Trusted, 0x0 = Untrusted
  [5] OTHER_PIXEL_DM_TRUSTED rw — Defines whether other accesses with the Pixel DM are trusted: 0x1 = Trusted, 0x0 = Untrusted
  [4] MCU_PIXEL_DM_TRUSTED rw — Defines whether MCU accesses with the Pixel DM are trusted: 0x1 = Trusted, 0x0 = Untrusted
  [3] PBE_PIXEL_DM_TRUSTED rw — Defines whether PBE accesses with the Pixel DM are trusted: 0x1 = Trusted, 0x0 = Untrusted
  [2] OTHER_VERTEX_DM_TRUSTED rw — Defines whether other accesses with the Vertex DM are trusted: 0x1 = Trusted, 0x0 = Untrusted
  [1] MCU_VERTEX_DM_TRUSTED rw — Defines whether MCU accesses with the Vertex DM are trusted: 0x1 = Trusted, 0x0 = Untrusted
  [0] PBE_VERTEX_DM_TRUSTED rw — Defines whether PBE accesses with the Vertex DM are trusted: 0x1 = Trusted, 0x0 = Untrusted
0xA100 CORE_MMRS_RGX_CR_SYS_BUS_SECURE reset 0x1
  [0] ENABLE rw — <p>0 = No System Bus Security</p><p>1 = System Bus Restricted</p>
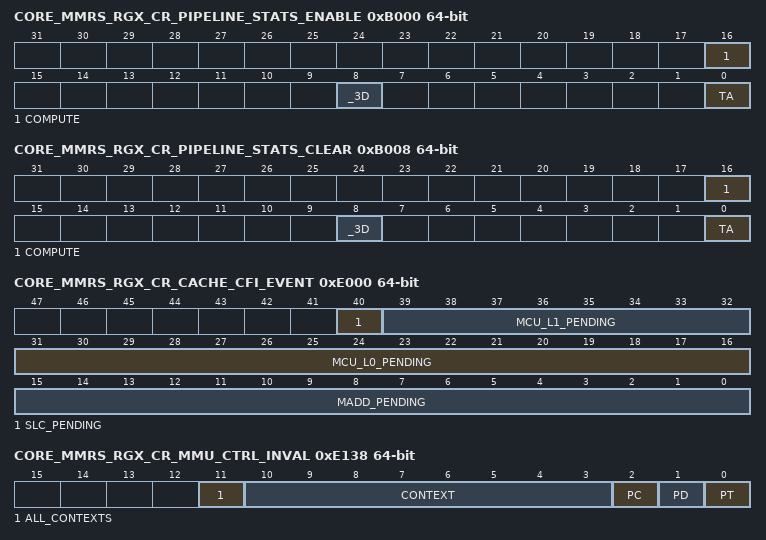
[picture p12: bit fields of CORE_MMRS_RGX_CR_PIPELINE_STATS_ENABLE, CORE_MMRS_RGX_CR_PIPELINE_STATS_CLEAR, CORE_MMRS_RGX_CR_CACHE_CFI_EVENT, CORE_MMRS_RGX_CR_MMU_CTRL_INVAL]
0xB000 CORE_MMRS_RGX_CR_PIPELINE_STATS_ENABLE
  [16] COMPUTE rw, [8] _3D rw, [0] TA rw
0xB008 CORE_MMRS_RGX_CR_PIPELINE_STATS_CLEAR
  [16] COMPUTE wo, [8] _3D wo, [0] TA wo
0xB010 CORE_MMRS_RGX_CR_PIPELINE_STATS_IA_VERTICES ro
  [63:0] COUNT
0xB018 CORE_MMRS_RGX_CR_PIPELINE_STATS_IA_PRIMITIVES ro
  [63:0] COUNT
0xB020 CORE_MMRS_RGX_CR_PIPELINE_STATS_VS_INVOCATIONS ro
  [63:0] COUNT
0xB038 CORE_MMRS_RGX_CR_PIPELINE_STATS_GS_INVOCATIONS ro
  [63:0] COUNT
0xB040 CORE_MMRS_RGX_CR_PIPELINE_STATS_GS_PRIMITIVES ro
  [63:0] COUNT
0xB048 CORE_MMRS_RGX_CR_PIPELINE_STATS_C_INVOCATIONS ro
  [63:0] COUNT
0xB050 CORE_MMRS_RGX_CR_PIPELINE_STATS_C_PRIMITIVES ro
  [63:0] COUNT
0xB058 CORE_MMRS_RGX_CR_PIPELINE_STATS_PS_INVOCATIONS ro
  [63:0] COUNT
0xB060 CORE_MMRS_RGX_CR_PIPELINE_STATS_CS_INVOCATIONS ro
  [63:0] COUNT
0xE000 CORE_MMRS_RGX_CR_CACHE_CFI_EVENT ro
  [40] SLC_PENDING — 1 Indicates there is a pending global CFI operation on the SLC cache
  [39:32] MCU_L1_PENDING — 1 Indicates there is a pending global CFI operation on the specified MCU L1 cache [there can be up to 8 MCU L1 caches depending on the number of clusters]
  [31:16] MCU_L0_PENDING — 1 Indicates there is a pending global CFI operation on the specified MCU L0 cache [there can be up to 16 MCU L0 caches depending on the number of clusters]
  [15:0] MADD_PENDING — 1 Indicates there is a pending global CFI operation on the specified MADD Texture cache [there can be up to 16 MADD caches depending on the number of clusters]
0xE138 CORE_MMRS_RGX_CR_MMU_CTRL_INVAL
  [11] ALL_CONTEXTS wo — When ALL_CONTEXTS is set, all context ids get invalidated [global invalidation]
  [10:3] CONTEXT wo — When ALL_CONTEXTS is not set, this field specifies the context id to be invalidated [per-context invalidation]
  [2] PC wo — Invalidates PC, PD & PT
  [1] PD wo — Invalidates PD & PT
  [0] PT wo — Invalidates PT
0xF220 CORE_MMRS_RGX_CR_BIF_BLACKPEARL_RTN_FIFO_WORD_COUNT ro
  [8:0] COUNTER
0xF228 CORE_MMRS_RGX_CR_BIF_JONES_RTN_FIFO_WORD_COUNT ro
  [8:0] COUNTER
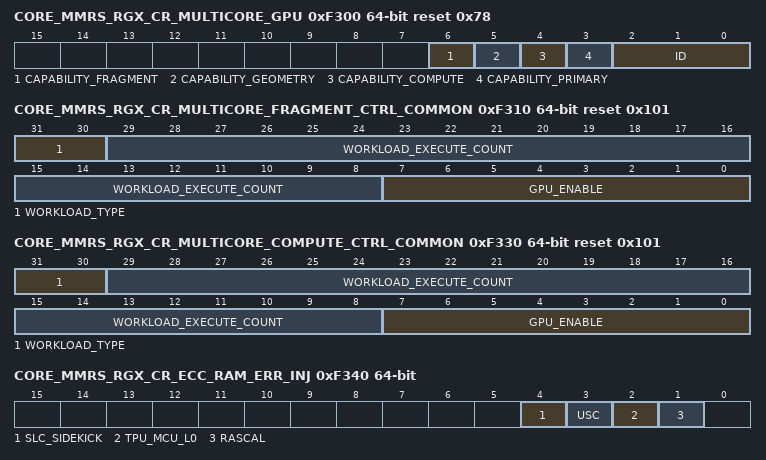
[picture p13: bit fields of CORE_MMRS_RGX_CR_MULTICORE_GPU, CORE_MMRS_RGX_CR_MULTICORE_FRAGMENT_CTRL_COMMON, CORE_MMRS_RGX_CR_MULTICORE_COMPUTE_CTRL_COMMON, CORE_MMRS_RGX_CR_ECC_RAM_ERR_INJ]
0xF300 CORE_MMRS_RGX_CR_MULTICORE_GPU ro reset 0x78
  [6] CAPABILITY_FRAGMENT — Whether or not this core has fragment capability. A value of 1 means it has the capability.
  [5] CAPABILITY_GEOMETRY — Whether or not this core has geometry capability. A value of 1 means it has the capability.
  [4] CAPABILITY_COMPUTE — Whether or not this core has compute capability. A value of 1 means it has the capability.
  [3] CAPABILITY_PRIMARY — If this field is set to one, then this core has job synchronisation capabilities [i. e. via its firmware scheduler] and can be used as a Primary core.
  [2:0] ID — The ID number of the GPU within the multicore system
0xF308 CORE_MMRS_RGX_CR_MULTICORE_SYSTEM ro reset 0x1
  [3:0] GPU_COUNT — The number of physical cores in this Primary-Secondary group of a multicore system. A value of zero is meaningless. This register is set via a top level pin.
0xF310 CORE_MMRS_RGX_CR_MULTICORE_FRAGMENT_CTRL_COMMON reset 0x101
  [31:30] WORKLOAD_TYPE rw — Sets the type of workload to be executed. 0 = Execute count is per tile-group [2x2 group of 16x16 tiles] for standard 3D renders and per two-tiles for Fast/Scale renders. 1 = Execute count is per row. Where a row is 4 [16x16] tiles high of the render width for standard 3D renders and 2 rows of [16x16] tiles for Fast/Scale renders. 2 = Reserved. 3 = Reserved.
  [29:8] WORKLOAD_EXECUTE_COUNT rw — The number of workloads to process in a run, where a workload is as identified by the RGX_CR_MULTICORE_FRAGMENT_CTRL_COMMON_WORKLOAD_TYPE register. This register must be the same across all instances in this Primary-Secondary group. Setting this register to zero means that all workloads will be processed.
  [7:0] GPU_ENABLE rw — An active high signal, one bit per GPU indicating if the fragment phase is active. Each GPU uses its RGX_CR_MULTICORE_FRAGMENT_CTRL_GPU_OFFSET register value to index into this register. This register must be the same across all instances in this Primary-Secondary group. Enable bits beyond GPU_COUNT shall be set to 0.
0xF318 CORE_MMRS_RGX_CR_MULTICORE_FRAGMENT_CTRL
  [2:0] GPU_OFFSET rw — The index of the GPU used in the calculation of the fragment Workload Distribution. This register shall be different per Primary/Secondary instance within a group. See the Workload Distribution Scheme section for further details. The offset must be contiguous within the active fragment group. See the Workload Distribution example for more details.
0xF330 CORE_MMRS_RGX_CR_MULTICORE_COMPUTE_CTRL_COMMON reset 0x101
  [31:30] WORKLOAD_TYPE rw — The type of workload per WORKLOAD_EXECUTE_COUNT. 0 = workgroup. 1, 2, 3 = reserved.
  [29:8] WORKLOAD_EXECUTE_COUNT rw — The number of compute workloads to process in a run. This register must be the same across all instances in this Primary-Secondary group. Setting this register to zero means that all workloads will be processed.
  [7:0] GPU_ENABLE rw — An active high signal, one bit per GPU indicating if the compute phase is active. Each GPU uses its RGX_CR_MULTICORE_COMPUTE_CTRL_GPU_OFFSET register value to index into this register. This register must be the same across all instances in this Primary-Secondary group. Enable bits beyond GPU_COUNT shall be set to 0.
0xF338 CORE_MMRS_RGX_CR_MULTICORE_COMPUTE_CTRL
  [2:0] GPU_OFFSET rw — The index of the GPU used in the calculation of the compute Workload Distribution. This register shall be different per Primary/Secondary instance within a group. The offset must be contiguous within the active compute group.
0xF340 CORE_MMRS_RGX_CR_ECC_RAM_ERR_INJ
  [4] SLC_SIDEKICK rw — ECC_RAM error injection for ALL blocks within SLC_SIDEKICK
  [3] USC rw — ECC_RAM error injection for ALL blocks within USC
  [2] TPU_MCU_L0 rw — ECC_RAM error injection for ALL blocks within TPU_MCU_L0
  [1] RASCAL rw — ECC_RAM error injection for ALL blocks within RASCAL
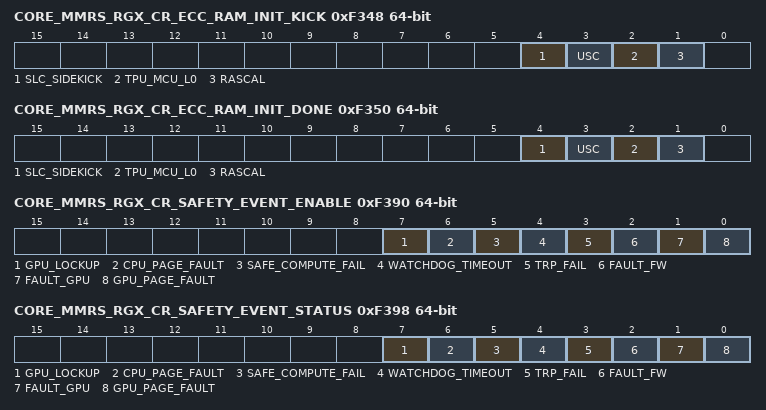
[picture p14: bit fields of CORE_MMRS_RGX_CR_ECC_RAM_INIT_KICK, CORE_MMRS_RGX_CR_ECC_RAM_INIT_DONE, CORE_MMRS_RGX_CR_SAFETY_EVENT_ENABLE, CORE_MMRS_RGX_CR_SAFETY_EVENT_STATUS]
0xF348 CORE_MMRS_RGX_CR_ECC_RAM_INIT_KICK
  [4] SLC_SIDEKICK wo — ECC_RAM Init kick for ALL blocks within SLC_SIDEKICK
  [3] USC wo — ECC_RAM Init kick for ALL blocks within USC
  [2] TPU_MCU_L0 wo — ECC_RAM Init kick for ALL blocks within TPU_MCU_L0
  [1] RASCAL wo — ECC_RAM Init kick for ALL blocks within RASCAL
0xF350 CORE_MMRS_RGX_CR_ECC_RAM_INIT_DONE ro
  [4] SLC_SIDEKICK — ECC_RAM Init kick for ALL blocks within SLC_SIDEKICK
  [3] USC — ECC_RAM Init kick for ALL blocks within USC
  [2] TPU_MCU_L0 — ECC_RAM Init kick for ALL blocks within TPU_MCU_L0
  [1] RASCAL — ECC_RAM Init kick for ALL blocks within RASCAL
0xF390 CORE_MMRS_RGX_CR_SAFETY_EVENT_ENABLE
  [7] GPU_LOCKUP rw — Set if GPU has locked up
  [6] CPU_PAGE_FAULT rw — Set if a CPU page fault has been detected.
  [5] SAFE_COMPUTE_FAIL rw — Set if workgroup protection checksum comparison has failed
  [4] WATCHDOG_TIMEOUT rw — Set if HW watchdog timer has timed out
  [3] TRP_FAIL rw — Set if TRP checksum check has failed
  [2] FAULT_FW rw — Set if a parity failure has been detected in FW processor
  [1] FAULT_GPU rw — Set if a parity failure has been detected in GPU
  [0] GPU_PAGE_FAULT rw — Set if a GPU page fault has been detected.
0xF398 CORE_MMRS_RGX_CR_SAFETY_EVENT_STATUS
  fields as CORE_MMRS_RGX_CR_SAFETY_EVENT_ENABLE
0xF3A0 CORE_MMRS_RGX_CR_SAFETY_EVENT_CLEAR
  [7] GPU_LOCKUP wo — Set if GPU has locked up
  [6] CPU_PAGE_FAULT wo — Set if a CPU page fault has been detected.
  [5] SAFE_COMPUTE_FAIL wo — Set if workgroup protection checksum comparison has failed
  [4] WATCHDOG_TIMEOUT wo — Set if HW watchdog timer has timed out
  [3] TRP_FAIL wo — Set if TRP checksum check has failed
  [2] FAULT_FW wo — Set if a parity failure has been detected in FW processor
  [1] FAULT_GPU wo — Set if a parity failure has been detected in GPU
  [0] GPU_PAGE_FAULT wo — Set if a GPU page fault has been detected.
0xF3A8 CORE_MMRS_RGX_CR_TRP_FAIL
  [0] PULSE wo
0xF3B0 CORE_MMRS_RGX_CR_FAULT_FW_STATUS ro
  [16] CPU_CORRECT — Set if a fault affecting the FW processor has been corrected
  [0] CPU_DETECT — Set if a fault affecting the FW processor has been detected
0xF3B8 CORE_MMRS_RGX_CR_FAULT_FW_CLEAR
  [16] CPU_CORRECT wo — Set if a fault affecting the FW processor has been corrected
  [0] CPU_DETECT wo — Set if a fault affecting the FW processor has been detected
0xF3C0 CORE_MMRS_RGX_CR_FAULT_GPU_STATUS ro
  [19] SLC_SIDEKICK_CORRECT — Set if a fault affecting any RAM in SLC_SIDEKICK layout block has been corrected.
  [18] USC_CORRECT — Set if a fault affecting any RAM in USC layout block has been corrected.
  [17] TPU_MCU_L0_CORRECT — Set if a fault affecting any RAM in TPU_MCU_L0 layout block has been corrected.
  [16] RASCAL_CORRECT — Set if a fault affecting any RAM in RASCAL layout block has been corrected.
  [3] SLC_SIDEKICK_DETECT — Set if a fault affecting any RAM in SLC_SIDEKICK layout block has been detected.
  [2] USC_DETECT — Set if a fault affecting any RAM in USC layout block has been detected.
  [1] TPU_MCU_L0_DETECT — Set if a fault affecting any RAM in TPU_MCU_L0 layout block has been detected.
  [0] RASCAL_DETECT — Set if a fault affecting any RAM in RASCAL layout block has been detected.
0xF3C8 CORE_MMRS_RGX_CR_FAULT_GPU_CLEAR
  [19] SLC_SIDEKICK_CORRECT wo — Set if a fault affecting any RAM in SLC_SIDEKICK layout block has been corrected.
  [18] USC_CORRECT wo — Set if a fault affecting any RAM in USC layout block has been corrected.
  [17] TPU_MCU_L0_CORRECT wo — Set if a fault affecting any RAM in TPU_MCU_L0 layout block has been corrected.
  [16] RASCAL_CORRECT wo — Set if a fault affecting any RAM in RASCAL layout block has been corrected.
  [3] SLC_SIDEKICK_DETECT wo — Set if a fault affecting any RAM in SLC_SIDEKICK layout block has been detected.
  [2] USC_DETECT wo — Set if a fault affecting any RAM in USC layout block has been detected.
  [1] TPU_MCU_L0_DETECT wo — Set if a fault affecting any RAM in TPU_MCU_L0 layout block has been detected.
  [0] RASCAL_DETECT wo — Set if a fault affecting any RAM in RASCAL layout block has been detected.
0xF3D0 CORE_MMRS_RGX_CR_FILTER_FAULT_CORRECTION
  [0] ENABLE rw — 0 - Only faults that were detected but not corrected are signaled . 1 - Faults that are detected or corrected are signaled.
0xF3D8 CORE_MMRS_RGX_CR_MTS_SAFETY_EVENT_ENABLE
  fields as CORE_MMRS_RGX_CR_SAFETY_EVENT_ENABLE
0xF3E0 CORE_MMRS_RGX_CR_SAFE_COMPUTE_FAIL
  [0] PULSE wo
0xF3E8 CORE_MMRS_RGX_CR_GPU_LOCKUP
  [0] PULSE wo
{0x20+0x10000*i} CORE_MMRS_RGX_CR_CORE_ID{i} ro reset 0x2400350068031C (i=1..7)
  [63:48] BRANCH_ID — B - Branch ID
  [47:32] VERSION_ID — V - Version ID
  [31:16] NUMBER_OF_SCALABLE_UNITS — N - Number of scalable Units
  [15:0] CONFIG_ID — C - Config ID
{0xB00+0x10000*i} CORE_MMRS_RGX_CR_MTS_SCHEDULE{i} (i=1..7)
  [8] HOST wo — Host Interrupte kick
  [7:6] PRIORITY wo — DataMaster Priority
  [5] CONTEXT wo
  [4] TASK wo
  [3:0] DM wo — DataMaster Type
{0xB98+0x10000*i} CORE_MMRS_RGX_CR_MTS_INTCTX{i} ro (i=1..7)
  [29:22] DM_HOST_SCHEDULE — A 1 bit counter per DM for host requests
  [15:8] DM_TIMER_SCHEDULE — A 1 bit counter per DM for timer requests
  [7:0] DM_INTERRUPT_SCHEDULE — A 1 bit counter per DM for interrupt requests
{0xBA0+0x10000*i} CORE_MMRS_RGX_CR_MTS_BGCTX{i} ro (i=1..7)
  [7:0] DM_NONCOUNTED_SCHEDULE — A 1 bit counter per DM for non-counted background request
{0xBA8+0x10000*i} CORE_MMRS_RGX_CR_MTS_BGCTX_COUNTED_SCHEDULE{i} ro (i=1..7)
  [8n+7:8n] DM{n} (n=0..5) — A 8 bit counter for DM{n}
